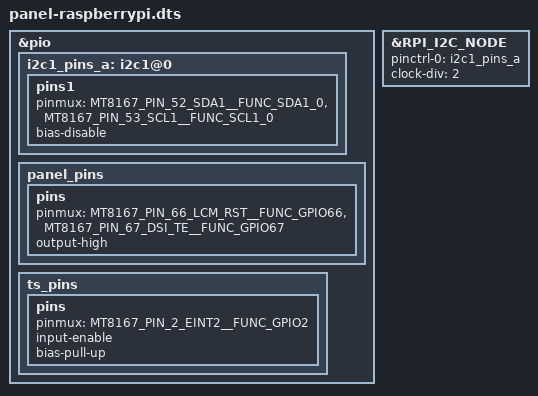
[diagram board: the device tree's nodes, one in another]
/dts-v1/;
/plugin/;

#define RPI_DSI_NODE dsi
#define RPI_I2C_NODE i2c1
#define RPI_MIPI_TX_NODE mipi_tx
#define RPI_PANEL_POWER_SUPPLY mt6392_vgp2_reg
#define RPI_TS_INTERRUPT 2

#include "panel-raspberrypi.dtsi"
#include "mt8167-pinfunc.h"

/ {
	fragment@3 {
		target = <&pio>;
		__overlay__ {
			i2c1_pins_a: i2c1@0 {
				pins1 {
					pinmux = <MT8167_PIN_52_SDA1__FUNC_SDA1_0>,
						 <MT8167_PIN_53_SCL1__FUNC_SCL1_0>;
					bias-disable;
				};
			};

			panel_pins: panel_pins {
				pins {
					pinmux = <MT8167_PIN_66_LCM_RST__FUNC_GPIO66>,
						 <MT8167_PIN_67_DSI_TE__FUNC_GPIO67>;
					output-high;
				};
			};

			ts_pins: ts_pins {
				pins {
					pinmux = <MT8167_PIN_2_EINT2__FUNC_GPIO2>;
					input-enable;
					bias-pull-up;
				};
			};
		};
	};

	fragment@4 {
		target = <&RPI_I2C_NODE>;
		__overlay__ {
			pinctrl-names = "default";
			pinctrl-0 = <&i2c1_pins_a>;
			clock-div = <2>;
		};
	};
};
